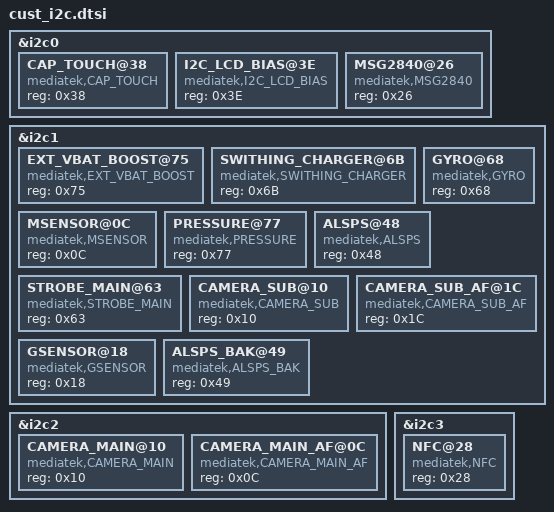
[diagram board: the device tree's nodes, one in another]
/*
 * Generated by MTK SP DrvGen Version 03.13.6 for MT6755. Copyright MediaTek Inc. (C) 2013.
 * Sat Dec 12 11:43:09 2015
 * Do Not Modify the File.
 */

/*************************
 * I2C DTSI File
*************************/

&i2c0 {
	CAP_TOUCH@38 {
		compatible = "mediatek,CAP_TOUCH";
		reg = <0x38>;
	};

	I2C_LCD_BIAS@3E {
		compatible = "mediatek,I2C_LCD_BIAS";
		reg = <0x3E>;
	};

	MSG2840@26 {
		compatible = "mediatek,MSG2840";
		reg = <0x26>;
	};

};

&i2c1 {
	EXT_VBAT_BOOST@75 {
		compatible = "mediatek,EXT_VBAT_BOOST";
		reg = <0x75>;
	};

	SWITHING_CHARGER@6B {
		compatible = "mediatek,SWITHING_CHARGER";
		reg = <0x6B>;
	};

	MSENSOR@0C {
		compatible = "mediatek,MSENSOR";
		reg = <0x0C>;
	};

	GYRO@68 {
		compatible = "mediatek,GYRO";
		reg = <0x68>;
	};

	PRESSURE@77 {
		compatible = "mediatek,PRESSURE";
		reg = <0x77>;
	};

	ALSPS@48 {
		compatible = "mediatek,ALSPS";
		reg = <0x48>;
	};

	STROBE_MAIN@63 {
		compatible = "mediatek,STROBE_MAIN";
		reg = <0x63>;
	};

	CAMERA_SUB@10 {
		compatible = "mediatek,CAMERA_SUB";
		reg = <0x10>;
	};

	CAMERA_SUB_AF@1C {
		compatible = "mediatek,CAMERA_SUB_AF";
		reg = <0x1C>;
	};
	GSENSOR@18 {
		compatible = "mediatek,GSENSOR";
		reg = <0x18>;
	};
	ALSPS_BAK@49 {
		compatible = "mediatek,ALSPS_BAK";
		reg = <0x49>;
	};

};

&i2c2 {
	CAMERA_MAIN@10 {
		compatible = "mediatek,CAMERA_MAIN";
		reg = <0x10>;
	};

	CAMERA_MAIN_AF@0C {
		compatible = "mediatek,CAMERA_MAIN_AF";
		reg = <0x0C>;
	};

};

&i2c3 {
	NFC@28 {
		compatible = "mediatek,NFC";
		reg = <0x28>;
	};

};

